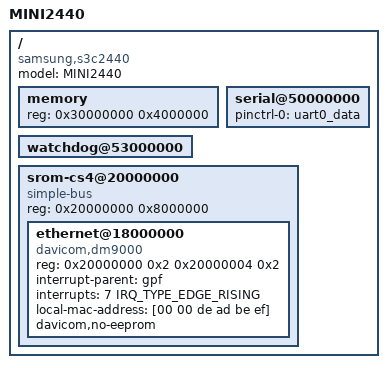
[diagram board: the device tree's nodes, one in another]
/*
 * SAMSUNG MINI2440 board device tree source
 *
 * Copyright (c) 2013 Heiko Stuebner <heiko@sntech.de>
 *
 * This program is free software; you can redistribute it and/or modify
 * it under the terms of the GNU General Public License version 2 as
 * published by the Free Software Foundation.
 */

/dts-v1/;
#include <dt-bindings/gpio/gpio.h>
#include <dt-bindings/interrupt-controller/irq.h>

#include "s3c2440.dtsi"

/ {
	model = "MINI2440";
	compatible = "samsung,s3c2440", "samsung,mini2440";

	memory {
		reg = <0x30000000 0x4000000>;
	};

	serial@50000000 {
		status = "okay";
		pinctrl-names = "default";
		pinctrl-0 = <&uart0_data>;
	};

	watchdog@53000000 {
		status = "okay";
	};

	srom-cs4@20000000 {
		compatible = "simple-bus";
		#address-cells = <1>;
		#size-cells = <1>;
		reg = <0x20000000 0x8000000>;
		ranges;
		ethernet@18000000 {
			compatible = "davicom,dm9000";
			reg = <0x20000000 0x2 0x20000004 0x2>;
			interrupt-parent = <&gpf>;
			interrupts = <7 IRQ_TYPE_EDGE_RISING>;
			local-mac-address = [00 00 de ad be ef];
			davicom,no-eeprom;
		};
	};
};
